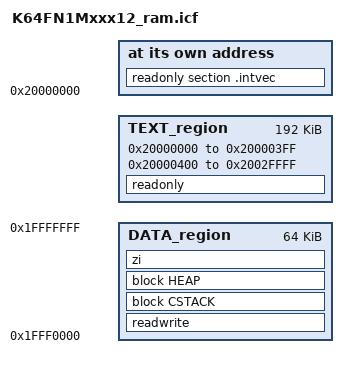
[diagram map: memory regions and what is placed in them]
/* Linker file for IAR ARM C Compiler */
define symbol m_interrupts_start       = 0x20000000;
define symbol m_interrupts_end         = 0x200003FF;      

define symbol m_text_start             = 0x20000400;
define symbol m_text_end               = 0x2002FFFF;      

define symbol m_data_start             = 0x1FFF0000;
define symbol m_data_end               = 0x1FFFFFFF;      

/*-Sizes-*/
define symbol __size_cstack__          = 0x2000;
define symbol __size_heap__            = 0x2000;
define exported symbol __VECTOR_TABLE  = m_interrupts_start;
define exported symbol __VECTOR_RAM    = m_interrupts_start;  
  
define memory mem with size = 4G;
define region TEXT_region = mem:[from m_interrupts_start to m_interrupts_end]
                          | mem:[from m_text_start to m_text_end];
define region DATA_region = mem:[from m_data_start to m_data_end];
  
define block CSTACK    with alignment = 8, size = __size_cstack__   { };
define block HEAP      with alignment = 8, size = __size_heap__     { };

do not initialize  { section .noinit };
  
place at address mem: m_interrupts_start    { readonly section .intvec };
place in TEXT_region                        { readonly };
place in DATA_region                        { readwrite, block CSTACK, block HEAP };
place in DATA_region                        { zi };
